# MCU_CPSW0_NUSS_ALE register map
Vendor: Texas Instruments
Peripheral module from a debugger description file (folder am65x).
Registers are 32-bit, read-write, reset values left out (the file's numbers can be read two ways) unless marked. A register's access mark holds for its fields unless they carry their own. Offsets are as the file gives them; lines under a group give offsets from that group; [hi:lo] are bit positions; {n}, {i} and the like mark numbered series; 'fields as' and 'values as' point back to an identical list; <NAME> marks a mode.

## MCU_CPSW0_NUSS_ALE
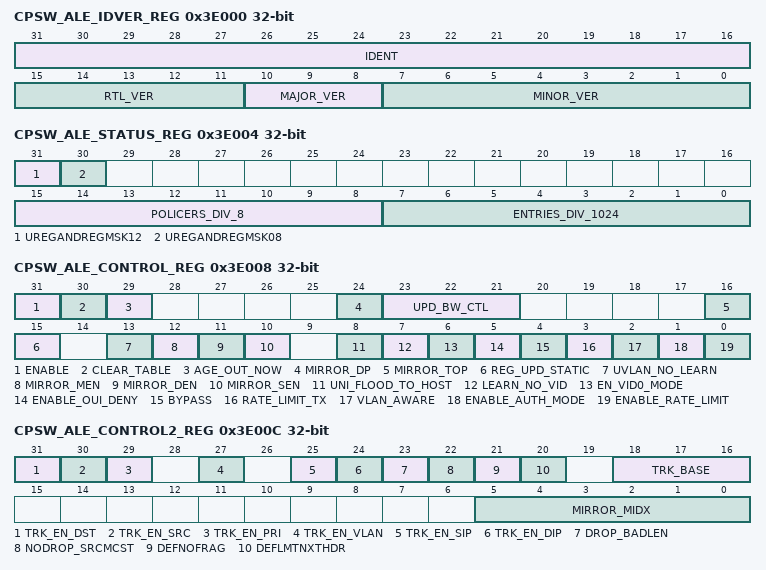
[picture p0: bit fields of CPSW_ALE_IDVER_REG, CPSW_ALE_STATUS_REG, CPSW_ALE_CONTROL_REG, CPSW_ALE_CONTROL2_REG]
0x3E000 CPSW_ALE_IDVER_REG ro — ALE Module and Version Register.
  [31:16] IDENT — ALE Identification Value
  [15:11] RTL_VER — ALE RTL Version Value
  [10:8] MAJOR_VER — ALE Major Version Value
  [7:0] MINOR_VER — ALE Minor Version Value
0x3E004 CPSW_ALE_STATUS_REG ro — ALE Status Register
  [31] UREGANDREGMSK12 — When set, the unregistered multicast field is a mask versus an index on 12 bit boundary in the ALE table.
  [30] UREGANDREGMSK08 — When set, the unregistered multicast field is a mask versus an index on 8 bit boundary in the ALE table.
  [15:8] POLICERS_DIV_8 — This is the number of policer engines the ALE implements divided by 8.
  [7:0] ENTRIES_DIV_1024 — The number of ALE entries in the ALE table divided by 1024
0x3E008 CPSW_ALE_CONTROL_REG — ALE Control Register
  [31] ENABLE — Enable ALE
  [30] CLEAR_TABLE — Clear ALE address table.
  [29] AGE_OUT_NOW — Age Out Address Table Now.
  [24] MIRROR_DP — Mirror Destination Port.
  [23:21] UPD_BW_CTL — The [23-21] UPD_BW_CTL field allows for up to 8 times the rate in which adds, updates, touches, writes, and aging updates can occur.
  [16] MIRROR_TOP — Mirror To Port.
  [15] REG_UPD_STATIC — Update Static Entries. Note: This bit should normally be cleared (value: 0h) for most switch configurations.
  [13] UVLAN_NO_LEARN — Unknown VLAN No Learn.
  [12] MIRROR_MEN — Mirror Match Entry Enable.
  [11] MIRROR_DEN — Mirror Destination Port Enable.
  [10] MIRROR_SEN — Mirror Source Port Enable.
  [8] UNI_FLOOD_TO_HOST — Unknown unicast packets flood to host
  [7] LEARN_NO_VID
  [6] EN_VID0_MODE — Enable VLAN ID = 0 Mode
  [5] ENABLE_OUI_DENY — Enable OUI Deny Mode.
  [4] BYPASS — ALE Bypass.
  [3] RATE_LIMIT_TX — Rate Limit Transmit mode
  [2] VLAN_AWARE — ALE VLAN Aware.
  [1] ENABLE_AUTH_MODE — Enable MAC Authorization Mode.
  [0] ENABLE_RATE_LIMIT — Enable Broadcast and Multicast Rate Limit
0x3E00C CPSW_ALE_CONTROL2_REG — ALE Control 2 Register
  [31] TRK_EN_DST — Trunk Enable Destination Address.
  [30] TRK_EN_SRC — Trunk Enable Source Address.
  [29] TRK_EN_PRI — Trunk Enable Priority.
  [27] TRK_EN_VLAN — Trunk Enable Inner VLAN.
  [25] TRK_EN_SIP — Trunk Enable Source IP Address.
  [24] TRK_EN_DIP — Trunk Enable Destination IP Address.
  [23] DROP_BADLEN — Drop Bad Length.Drops any packet that the 802.3 length field is larger than the packet. Ethertypes 0-1500 are 802.3 lengths, all others are Ether types.
  [22] NODROP_SRCMCST — No Drop Source Multicast.Disables the dropping of any source address with the multicast bit set.
  [21] DEFNOFRAG — Default No Frag.Causes an IPv4 fragmented packet to be dropped if a VLAN entry is not found.
  [20] DEFLMTNXTHDR — Default Limit Next Header.Causes an IPv4 protocol or IPv6 next header packet to be dropped if a VLAN entry is not found and the protocol or next header does not match the
  [18:16] TRK_BASE — Trunk Base.
  [5:0] MIRROR_MIDX — Mirror Index.
0x3E010 CPSW_ALE_PRESCALE_REG — ALE Prescale Register
  [19:0] PRESCALE — ALE Prescale.
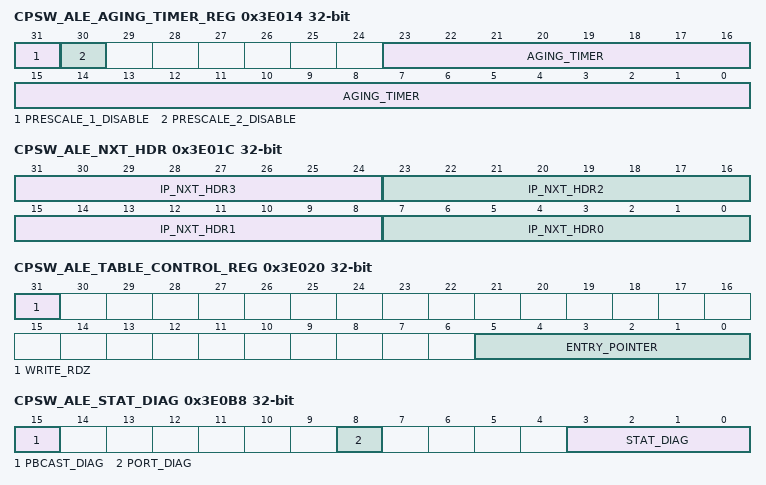
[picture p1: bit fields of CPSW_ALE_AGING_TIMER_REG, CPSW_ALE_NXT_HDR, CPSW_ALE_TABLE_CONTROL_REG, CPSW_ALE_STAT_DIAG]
0x3E014 CPSW_ALE_AGING_TIMER_REG — ALE Aging Control Register
  [31] PRESCALE_1_DISABLE — ALE Prescaler 2 Disable.
  [30] PRESCALE_2_DISABLE — ALE Prescaler 1 Disable.
  [23:0] AGING_TIMER — ALE Aging Timer.
0x3E01C CPSW_ALE_NXT_HDR — The ALE Next Header Register is used to limit the IPv6 Next header or IPv4 Protocol values found in the IP header. It is enabled via the LIMIT_NEXT_HEADER bit in the VLAN entry (see ). All four fields (IP_NXT_HDR0 to IP_NXT_HDR3) are compared when enabled, so if only one is required, set them all to the one value to be tested.
  [31:24] IP_NXT_HDR3 — The IP_NXT_HDR3 is the forth protocol or next header compared when enabled.
  [23:16] IP_NXT_HDR2 — The IP_NXT_HDR2 is the third protocol or next header compared when enabled.
  [15:8] IP_NXT_HDR1 — The IP_NXT_HDR1 is the second protocol or next header compared when enabled.
  [7:0] IP_NXT_HDR0 — The IP_NXT_HDR0 is the first protocol or next header compared when enabled.
0x3E020 CPSW_ALE_TABLE_CONTROL_REG — ALE Table Control Register
  [31] WRITE_RDZ — Table Write.
  [5:0] ENTRY_POINTER — The table index is used to determine which lookup table entry is read or written.
0x3E034 CPSW_ALE_TABLE_WORD2_REG — ALE LUT Table Word 2 Register
  [6:0] ENTRY_71_64 — Table Entry bits [71-64]
0x3E038 CPSW_ALE_TABLE_WORD1_REG — ALE LUT Table Word 1 Register
  [31:0] ENTRY_63_32 — Table Entry bits [63-32]
0x3E03C CPSW_ALE_TABLE_WORD0_REG — ALE LUT Table Word 0 Register
  [31:0] ENTRY_31_0 — Table Entry bits [31-0]
0x3E090 CPSW_ALE_UNKNOWN_VLAN_REG — ALE Unknown VLAN Member Mask Register
  [1:0] LIST — Unknown VLAN Member List.
0x3E094 CPSW_ALE_UNKNOWN_MCAST_FLOOD_REG — ALE Unknown VLAN Unregistered Multicast Flood Mask Register
  [1:0] MASK — Unknown VLAN Unregister Multicast Flood Mask.
0x3E098 CPSW_ALE_UNKNOWN_REG_MCAST_FLOOD_REG — ALE Unknown VLAN Registered Multicast Flood Mask Register Register
  [1:0] MASK — Unknown VLAN Register Multicast Flood Mask.
0x3E09C CPSW_ALE_FORCE_UNTAGGED_EGRESS_REG — ALE Unknown VLAN force Untagged Egress Mask Register Register
  [1:0] MASK — Unknown VLAN Force Untagged Egress Mask.
0x3E0B8 CPSW_ALE_STAT_DIAG — The ALE Statistic Output Diagnostic Register allows the output statistics to diagnose the software counters. This register is for diagnostic only.
  [15] PBCAST_DIAG — When set and the PORT_DIAG is set to zero, will allow all ports to see the same stat diagnostic increment.
  [8] PORT_DIAG — The port selected that a received packet will cause the selected error to increment
  [3:0] STAT_DIAG — When non-zero this field will cause the selected statistic to increment on the next frame received (for the selected port).0h = Disabled1h = Destination Equal Source Drop Stat will count2h = VLAN Ingress Check Drop Stat will count3h = Source Multicast Drop Stat will count4h = Dual VLAN Drop Stat will count5h = Ether Type length error Drop Stat will count6h = Next Hop Limit Drop Stat will count7h = IPv4 Fragment Drop Stat will count8h = Classifier Hit Stat will count9h = Classifier Red Drop Stat will countAh = Classifier Yellow Drop Stat will countBh = ALE Overflow Drop Stat will countCh = Rate Limit Drop Stat will countDh = Blocked Address Drop Stat will countEh = Secure Address Drop Stat will countFh = Authorization Drop Stat will count
0x3E0BC CPSW_ALE_OAM_LB_CTRL — The ALE OAM Control Register allows ports to be put into OAM Loopback, only non-supervisor packets are looped back to the source port.
  [1:0] OAM_LB_CTRL — The OAM_LB_CTRL bit field allows any port to be put into OAM loopback, that is any packet received will be returned to the same port with an
0x3E0C0 CPSW_ALE_VLAN_MASK_MUX0_REG ro — ALE Mask Mux 0 Register
  [1:0] MASK — VLAN Mask Mux x.
{0x3E0C0+4i} CPSW_ALE_VLAN_MASK_MUX{i}_REG (i=1..7) — ALE Mask Mux {i} Register
  [1:0] MASK — VLAN Mask Mux x.
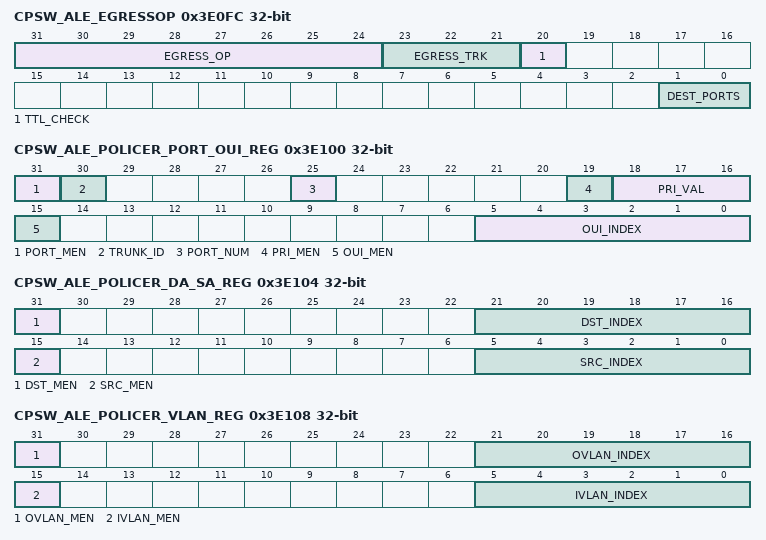
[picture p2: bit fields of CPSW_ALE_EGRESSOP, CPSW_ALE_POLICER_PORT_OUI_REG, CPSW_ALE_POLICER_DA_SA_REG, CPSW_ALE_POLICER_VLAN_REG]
0x3E0FC CPSW_ALE_EGRESSOP — InterVLAN routing is supported on SR2.0 only. The ALE Egress Operation Register allows enabled classifiers with any match like IPSA or IPDA to use the CPSW Egress Packet Operations Inter VLAN Routing sub functions. If the packet was destined for the host or is destined to any port without any errors, but matches a classifier that has a programmed egress opcode, it will be forwarded to the destination ports where the destination ports will use their egress opcode entry to modify the packet. InterVLAN routing and mirroring need to be understood, they are orthogonal functions. Care must be taken not to violate VLAN rules as this can redirect packets based on classifier matches.
  [31:24] EGRESS_OP — The Egress Operation defines the operation performed by the CPSW Egress Packet Operations0h = NOP1-n = Defines which egress Operation will be performed. This allows Inter VLAN routing to be configured for high bandwidth traffic, reducing CPU load.FFh = Swaps source address (SA) and destination address (DA) of packet, this is intended to allow OAM diagnostics for a link.
  [23:21] EGRESS_TRK — The Egress Trunk Index is the calculated trunk index from the SA, DA or VLAN if modified to that InterVLAN routing will work on trunks as well. The DA, SA and VLAN are ignored for trunk generation on InterVLAN Routing so that this field is the index generated from the Egress Op replacements exclusive ORed together into a three bit index.
  [20] TTL_CHECK — The TTL Check will cause any packet that fails TTL checks to not be routed to the Inter VLAN Routing sub functions. The packet will be routed to the host it was destined to.
  [1:0] DEST_PORTS — The Destination Ports is a list of the ports the classified packet will be set to. If a destination is a Trunk, all the port bits for that trunk must be set.
0x3E100 CPSW_ALE_POLICER_PORT_OUI_REG — Policer Port Frame Priority Register
  [31] PORT_MEN — Port Match Enable.
  [30] TRUNK_ID
  [25] PORT_NUM — Port Number.
  [19] PRI_MEN — Priority Match Enable.
  [18:16] PRI_VAL — Priority Value.
  [15] OUI_MEN — OUI Match Enable.
  [5:0] OUI_INDEX — OUI Table Entry Index.
0x3E104 CPSW_ALE_POLICER_DA_SA_REG — Policer Destination and Source Address Register
  [31] DST_MEN — Destination Address Match Enable.
  [21:16] DST_INDEX — Destination Address Table Entry Index.
  [15] SRC_MEN — Source Address Match Enable.
  [5:0] SRC_INDEX — Source Address Table Entry Index.
0x3E108 CPSW_ALE_POLICER_VLAN_REG — Outer VLAN and Inner VLAN Address Register
  [31] OVLAN_MEN — Outer VLAN Match Enable.
  [21:16] OVLAN_INDEX — Outer VLAN Table Entry Index.
  [15] IVLAN_MEN — Inner VLAN Match Enable.
  [5:0] IVLAN_INDEX — Inner VLAN Table Entry Index.
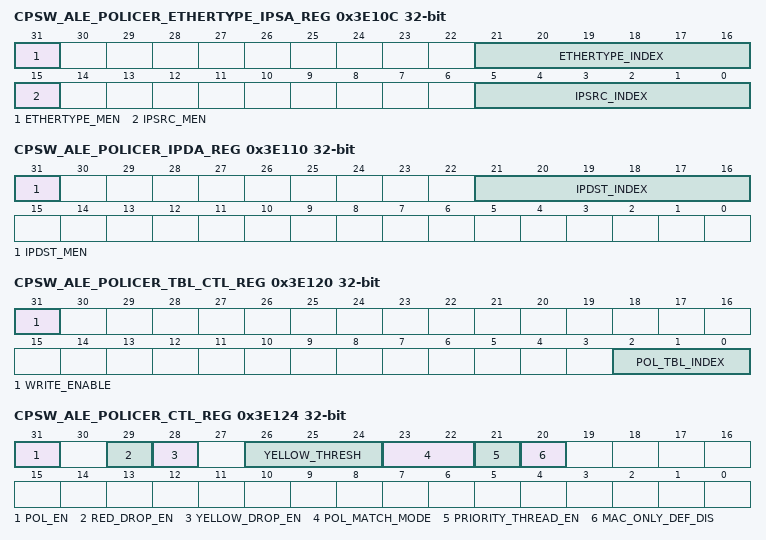
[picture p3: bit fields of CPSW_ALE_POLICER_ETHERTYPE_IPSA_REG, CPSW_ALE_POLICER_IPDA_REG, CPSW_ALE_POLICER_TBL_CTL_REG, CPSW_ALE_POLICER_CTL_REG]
0x3E10C CPSW_ALE_POLICER_ETHERTYPE_IPSA_REG — Ether Type and IP Source Address Register
  [31] ETHERTYPE_MEN — EtherType Match Enable.
  [21:16] ETHERTYPE_INDEX — EtherType Table Entry Index.
  [15] IPSRC_MEN — IP Source Address Match Enable.
  [5:0] IPSRC_INDEX — IP Source Address Table Entry Index.
0x3E110 CPSW_ALE_POLICER_IPDA_REG — IP Destination Address Register
  [31] IPDST_MEN — IP Destination Address Match Enable.
  [21:16] IPDST_INDEX — IP Destination Address Table Entry Index.
0x3E118 CPSW_ALE_POLICER_PIR_REG — PIR Idle Increment Value Register
  [31:0] PRI_IDLE_INC_VAL — Peak Information Rate Idle Increment Value.
0x3E11C CPSW_ALE_POLICER_CIR_REG — CIR Idle Increment Value Register
  [31:0] CIR_IDLE_INC_VAL — Committed Information Idle Increment Value.
0x3E120 CPSW_ALE_POLICER_TBL_CTL_REG — Policing Table Control Register
  [31] WRITE_ENABLE
  [2:0] POL_TBL_INDEX — Policer Entry Index.
0x3E124 CPSW_ALE_POLICER_CTL_REG — Policing Control Register
  [31] POL_EN — Policing Enable.
  [29] RED_DROP_EN — RED Drop Enable.
  [28] YELLOW_DROP_EN — WELLOW Drop Enable.
  [26:24] YELLOW_THRESH — Yellow Threshold.
  [23:22] POL_MATCH_MODE — Policing Match Mode.
  [21] PRIORITY_THREAD_EN — Priority Thread Enable.This field determines if priority is ORed to the default thread when no classifiers hit and the default thread is enabled.
  [20] MAC_ONLY_DEF_DIS — MAC Only Default Disable.This field when set disables the default thread on MAC Only Ports. That is the default thread will be {port,priority}. If the traffic matches a classifier with a thread mapping, the classifier thread mapping still occurs.
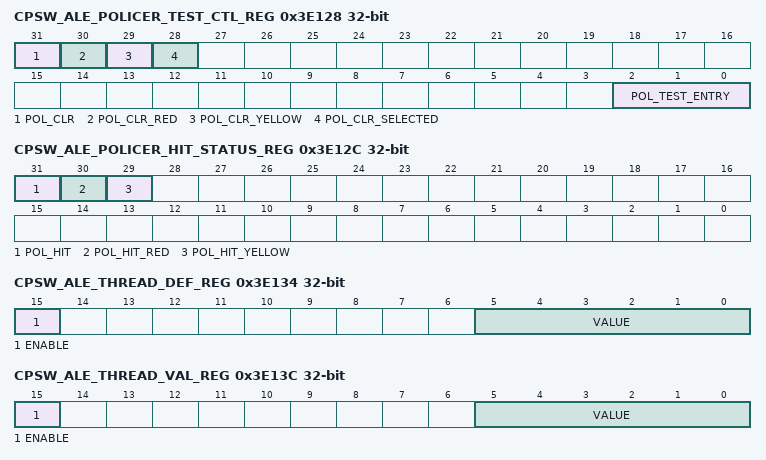
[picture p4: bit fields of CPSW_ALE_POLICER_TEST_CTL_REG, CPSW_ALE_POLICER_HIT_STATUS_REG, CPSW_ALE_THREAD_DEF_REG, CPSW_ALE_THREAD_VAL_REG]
0x3E128 CPSW_ALE_POLICER_TEST_CTL_REG — Policing Test Control Register
  [31] POL_CLR — Policer Clear.
  [30] POL_CLR_RED — Policer Clear RED.
  [29] POL_CLR_YELLOW — Policer Clear YELLOW.
  [28] POL_CLR_SELECTED — Police Clear Selected.
  [2:0] POL_TEST_ENTRY — Policer Test Index.
0x3E12C CPSW_ALE_POLICER_HIT_STATUS_REG ro — Policing Hit Status Register
  [31] POL_HIT — Policer Hit.
  [30] POL_HIT_RED — Policer Hit RED.
  [29] POL_HIT_YELLOW — Policer Hit YELLOW.
0x3E134 CPSW_ALE_THREAD_DEF_REG — THREAD Mapping Default Value Register
  [15] ENABLE — Default Tread Enable.
  [5:0] VALUE — Default Thread Value.
0x3E138 CPSW_ALE_THREAD_CTL_REG — THREAD Mapping Control Register
  [2:0] ENTRY_PTR — Classifier Index.
0x3E13C CPSW_ALE_THREAD_VAL_REG — THREAD Mapping Value Register
  [15] ENABLE — Thread Enable.
  [5:0] VALUE — Thread Value.
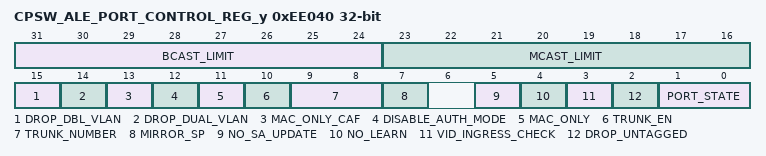
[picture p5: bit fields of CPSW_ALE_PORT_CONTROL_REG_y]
0xEE040 CPSW_ALE_PORT_CONTROL_REG_y — ALE Port Control 0 to 1 Register Offset = 0003E040h + (y * 4h); where y = 0 to 1
  [31:24] BCAST_LIMIT — Broadcast Packet Rate Limit.
  [23:16] MCAST_LIMIT — Multicast Packet Rate Limit.
  [15] DROP_DBL_VLAN — Drop Double VLAN.
  [14] DROP_DUAL_VLAN
  [13] MAC_ONLY_CAF — Mac Only Copy All Frames.
  [12] DISABLE_AUTH_MODE — Disable Port authorization.
  [11] MAC_ONLY
  [10] TRUNK_EN — Trunk Enable.
  [9:8] TRUNK_NUMBER
  [7] MIRROR_SP — Mirror Source Port.
  [5] NO_SA_UPDATE — No Source Address Update.
  [4] NO_LEARN
  [3] VID_INGRESS_CHECK — VLAN Ingress Check.
  [2] DROP_UNTAGGED — If Drop Untagged.
  [1:0] PORT_STATE
